# MM32F103xx register map
File version: 1.08
Registers are 32-bit, read-write, reset 0x0 unless marked. A register's access mark holds for its fields unless they carry their own. Offsets are from the block's base; lines under a group give offsets from that group; [hi:lo] are bit positions; {n}, {i} and the like mark numbered series; 'fields as' and 'values as' point back to an identical list; <NAME> marks a mode.

## Memory map
0x40000000 TIM2 size 0x400 — General purpose timer
0x40000400 TIM3 size 0x400
0x40000800 TIM4 size 0x400
0x40002800 RTC size 0x400 — Real time clock
0x40002C00 WWDG size 0x60 — Window watchdog
0x40003000 IWDG size 0x400 — Independent watchdog
0x40003800 SPI2 size 0x400
0x40004400 UART2 size 0x400
0x40004800 UART3 size 0x400
0x40005400 I2C1 size 0x400 — Inter integrated circuit
0x40005800 I2C2 size 0x400
0x40005C00 USB size 0x400 — Universal serial bus full-speed device interface
0x40006400 CAN size 0x400 — Controller area network
0x40006C00 BKP size 0x3F0 — Backup registers
0x40007000 PWR size 0x400 — Power control
0x40007080 DBG size 0x400 — Debug support
0x40010000 AFIO size 0x400 — Alternate function I/O
0x40010400 EXTI size 0x400 — External interrupt/event controller
0x40010800 GPIOA size 0x400 — General purpose I/O
0x40010C00 GPIOB size 0x400
0x40011000 GPIOC size 0x400
0x40011400 GPIOD size 0x400
0x40011800 GPIOE size 0x400
0x40012400 ADC1 size 0x400 — Analog to digital converter 1
0x40012800 ADC2 size 0x400 — Analog to digital converter 1
0x40012C00 TIM1 size 0x400 — Advanced timer
0x40013000 SPI1 size 0x400 — Serial peripheral interface
0x40013800 UART1 size 0x400 — Universal asynchronous receiver transmitter
0x40020000 DMA1 size 0x400 — DMA1 controller
0x40021000 RCC size 0x400 — Reset and clock control
0x40022000 FLASH size 0x400
0x40023000 CRC size 0x400 — CRC calculation unit
0x40026000 AES size 0x400 — Advanced Encryption Standard

## Interrupts
0 WWDG — Window Watchdog interrupt
1 PVD (PWR) — PVD through EXTI line detection interrupt
2 TAMPER (EXTI) — Tamper interrupt
3 RTC — RTC global interrupt
4 FLASH — Flash global interrupt
5 RCC — RCC global interrupt
6 EXTI0 (EXTI) — EXTI Line0 interrupt
7 EXTI1 (EXTI) — EXTI Line1 interrupt
8 EXTI2 (EXTI) — EXTI Line2 interrupt
9 EXTI3 (EXTI) — EXTI Line3 interrupt
10 EXTI4 (EXTI) — EXTI Line4 interrupt
11 DMA1_Channel1 (DMA1) — DMA1 Channel1 global interrupt
12 DMA1_Channel2 (DMA1) — DMA1 Channel2 global interrupt
13 DMA1_Channel3 (DMA1) — DMA1 Channel3 global interrupt
14 DMA1_Channel4 (DMA1) — DMA1 Channel4 global interrupt
15 DMA1_Channel5 (DMA1) — DMA1 Channel5 global interrupt
16 DMA1_Channel6 (DMA1) — DMA1 Channel6 global interrupt
17 DMA1_Channel7 (DMA1) — DMA1 Channel7 global interrupt
18 ADC (ADC1, ADC2) — ADC global interrupt
19 USB_FS (USB) — USB Device FS
21 CAN1_RX1 (CAN) — CAN1 RX1 interrupts
23 EXTI9_5 (EXTI) — EXTI Line[9_5] interrupts
24 TIM1_BRK (TIM1) — TIM1 break interrupt
25 TIM1_UP (TIM1) — TIM1 update interrupt
26 TIM1_TRG_COM (TIM1) — TIM1 trigger and communicate interrupt
27 TIM1_CC (TIM1) — TIM1 Capture Compare interrupt
28 TIM2 — TIM2 global interrupt
29 TIM3 — TIM3 global interrupt
30 TIM4 — TIM4 global interrupt
31 I2C1_EV (I2C1) — I2C1 event interrupt
33 I2C2_EV (I2C2) — I2C2 event interrupt
35 SPI1 — SPI1 global interrupt
36 SPI2 — SPI2 global interrupt
37 UART1 — UART1 global interrupt
38 UART2 — UART2 global interrupt
39 UART3 — UART3 global interrupt
40 EXTI15_10 (EXTI) — EXTI Line[15_10] interrupts
41 RTCAlarm (RTC) — RTC Alarms through EXTI line interrupt
45 AES — AES global interrupt

## ADC1 — Analog to digital converter 1
Base 0x40012400
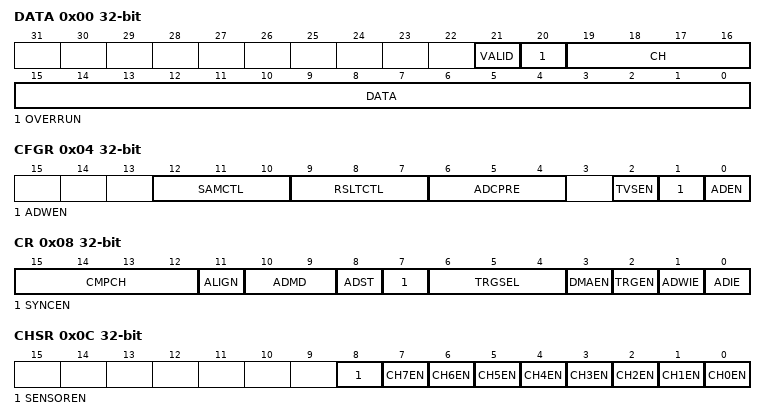
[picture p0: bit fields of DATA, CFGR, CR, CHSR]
0x00 DATA ro
  [21] VALID — Valid flag
  [20] OVERRUN — Overrun flag
  [19:16] CH — ADC current channel convert data
  [15:0] DATA — Transfer data
0x04 CFGR — Configure register
  [12:10] SAMCTL — Channel x Sample time selection
  [9:7] RSLTCTL — Resolution
  [6:4] ADCPRE — ADC prescaler
  [2] TVSEN — Temperature sensor enable
  [1] ADWEN — ADC window comparison enable
  [0] ADEN — ADC enable
0x08 CR — Control register
  [15:12] CMPCH — Window comparison channel selection
  [11] ALIGN — Data alignment
  [10:9] ADMD — ADC mode
  [8] ADST — ADC start
  [7] SYNCEN — Two ADC synchronous conversion enable
  [6:4] TRGSEL — External trigger selection
  [3] DMAEN — Direct memory access enable
  [2] TRGEN — External trigger enable
  [1] ADWIE — ADC window comparator interrupt enable
  [0] ADIE — ADC interrupt enable
0x0C CHSR — Channel select register
  [8] SENSOREN — Temperature Sensor enable
  [n] CH{n}EN (n=0..7) — Analog input channel {n} enable
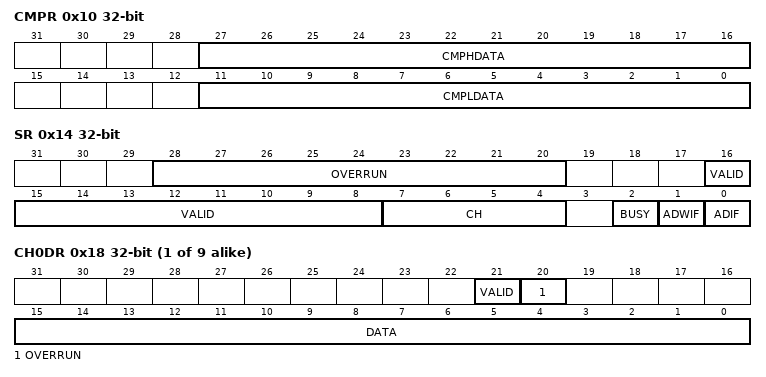
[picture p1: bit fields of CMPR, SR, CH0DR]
0x10 CMPR — Compare register
  [27:16] CMPHDATA — Compare data high limit
  [11:0] CMPLDATA — Compare data low limit
0x14 SR ro — Status register
  [28:20] OVERRUN — Overrun flag
  [16:8] VALID — Valid flag
  [7:4] CH — Current conversion channel
  [2] BUSY
  [1] ADWIF — ADC window comparator interrupt flag
  [0] ADIF — ADC interrupt flag
{0x18+4i} CH{i}DR ro (i=0..8) — Channel {i} data register
  [21] VALID — Valid flag
  [20] OVERRUN — Overrun flag
  [15:0] DATA — Transfer data

## ADC2 — Analog to digital converter 1
Base 0x40012800
Registers as ADC1; these are added or differ:
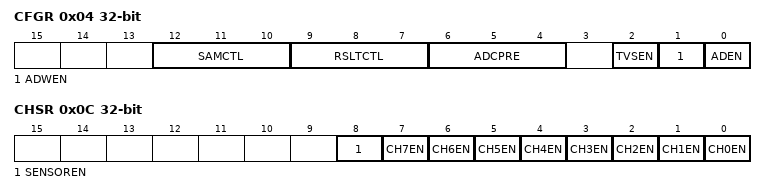
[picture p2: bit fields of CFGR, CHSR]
0x04 CFGR — Configure register
  [12:10] SAMCTL — Channel x Sample time selection
  [9:7] RSLTCTL — Resolution
  [6:4] ADCPRE — ADC prescaler
  [2] TVSEN — Reference voltage enable
  [1] ADWEN — ADC window comparison enable
  [0] ADEN — ADC enable
0x0C CHSR — Channel select register
  [8] SENSOREN — Reference voltage enable
  [n] CH{n}EN (n=0..7) — Analog input channel {n} enable
